VERSION ""

NS_ :

BS_:

BU_:

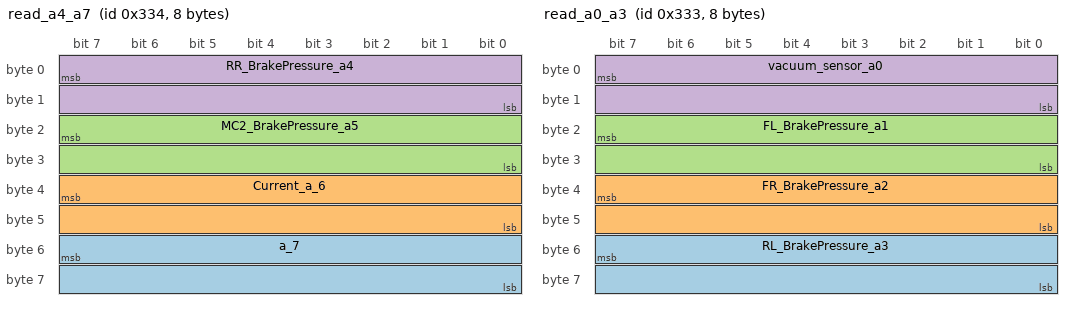
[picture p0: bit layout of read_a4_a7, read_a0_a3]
BO_ 820 read_a4_a7: 8 Vector__XXX
 SG_ a_7 : 55|16@0- (0.001,0) [-32.768|32.767] "Volts" Vector__XXX
 SG_ Current_a_6 : 39|16@0- (0.1,0) [-3276800|3276700] "Ampers" Vector__XXX
 SG_ MC2_BrakePressure_a5 : 23|16@0- (0.074266,0) [-32.768|32.767] "Bars" Vector__XXX
 SG_ RR_BrakePressure_a4 : 7|16@0- (0.073984,-0) [-2459.570712|2388.970728] "Bars" Vector__XXX

BO_ 819 read_a0_a3: 8 Vector__XXX
 SG_ RL_BrakePressure_a3 : 55|16@0- (0.074982,-0) [-2493.398176|2420.547194] "Bars" Vector__XXX
 SG_ FR_BrakePressure_a2 : 39|16@0- (0.074266,0) [-2495.1|2420.025] "Bars" Vector__XXX
 SG_ FL_BrakePressure_a1 : 23|16@0- (0.074266,0) [-2469.930288|2397.092022] "Bars" Vector__XXX
 SG_ vacuum_sensor_a0 : 7|16@0- (0.0227,1.9771) [-741.8565|745.788] "kPa" Vector__XXX

BA_DEF_ BU_  "ISO11783PDDVersion" ENUM  "0","1","2","3","4";
BA_DEF_ BU_  "ISO11783IOPVersion" ENUM  "0","1","2","3","4";
BA_DEF_ BO_  "SingleFrame" INT 0 1;
BA_DEF_ SG_  "SigType" ENUM  "Default","Range","RangeSigned","ASCII","Discrete","Control","ReferencePGN","DTC","StringDelimiter","StringLength","StringLengthControl";
BA_DEF_ SG_  "GenSigEVName" STRING ;
BA_DEF_ SG_  "GenSigILSupport" ENUM  "No","Yes";
BA_DEF_ SG_  "GenSigSendType" ENUM  "Cyclic","OnWrite","OnWriteWithRepetition","OnChange","OnChangeWithRepetition","IfActive","IfActiveWithRepetition","NoSigSendType";
BA_DEF_ SG_  "GenSigStartValue" INT 0 2147483647;
BA_DEF_ BO_  "GenMsgILSupport" ENUM  "No","Yes";
BA_DEF_ BU_  "NmStationAddress" INT 0 255;
BA_DEF_ BO_  "GenMsgSendType" ENUM  "cyclic","NotUsed","IfActive","NotUsed","NotUsed","NotUsed","NotUsed","NotUsed","noMsgSendType";
BA_DEF_ BO_  "GenMsgRequestable" INT 0 1;
BA_DEF_  "DBName" STRING ;
BA_DEF_  "BusType" STRING ;
BA_DEF_  "ProtocolType" STRING ;
BA_DEF_ BO_  "VFrameFormat" ENUM  "StandardCAN","ExtendedCAN","reserved","J1939PG";
BA_DEF_DEF_  "ISO11783PDDVersion" "3";
BA_DEF_DEF_  "ISO11783IOPVersion" "3";
BA_DEF_DEF_  "SingleFrame" 1;
BA_DEF_DEF_  "SigType" "Default";
BA_DEF_DEF_  "GenSigEVName" "Env@Nodename_@Signame";
BA_DEF_DEF_  "GenSigILSupport" "Yes";
BA_DEF_DEF_  "GenSigSendType" "NoSigSendType";
BA_DEF_DEF_  "GenSigStartValue" 0;
BA_DEF_DEF_  "GenMsgILSupport" "Yes";
BA_DEF_DEF_  "NmStationAddress" 254;
BA_DEF_DEF_  "GenMsgSendType" "noMsgSendType";
BA_DEF_DEF_  "GenMsgRequestable" 1;
BA_DEF_DEF_  "DBName" "";
BA_DEF_DEF_  "BusType" "CAN";
BA_DEF_DEF_  "ProtocolType" "ISO11783";
BA_DEF_DEF_  "VFrameFormat" "J1939PG";
BA_ "DBName" "ni6002";
BA_ "VFrameFormat" BO_ 820 0;
BA_ "VFrameFormat" BO_ 819 0;
BA_ "GenSigStartValue" SG_ 820 RR_BrakePressure_a4 1.92080108066636E-13;
BA_ "GenSigStartValue" SG_ 819 FL_BrakePressure_a1 489.887700966795;
